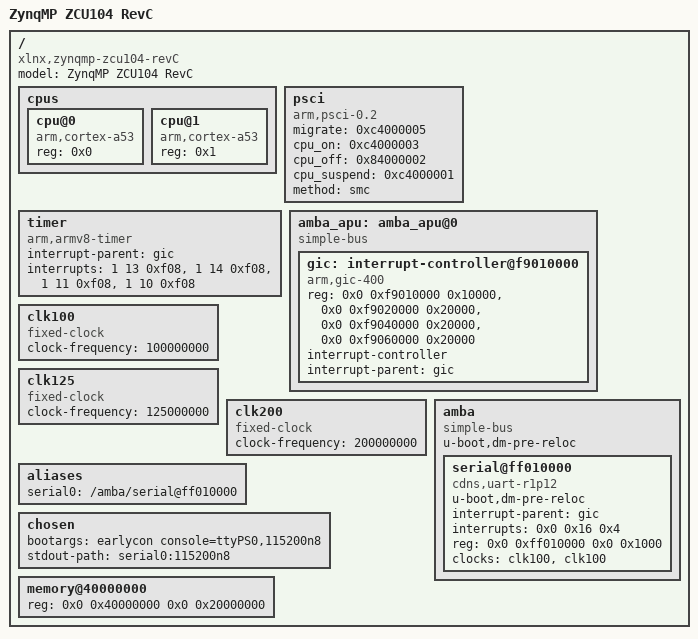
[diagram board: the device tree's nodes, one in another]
/dts-v1/;

/ {
	compatible = "xlnx,zynqmp-zcu104-revC", "xlnx,zynqmp-zcu104", "xlnx,zynqmp";
	#address-cells = <0x2>;
	#size-cells = <0x2>;
	model = "ZynqMP ZCU104 RevC";

	cpus {
		#address-cells = <0x1>;
		#size-cells = <0x0>;

		cpu@0 {
			compatible = "arm,cortex-a53", "arm,armv8";
			device_type = "cpu";
			reg = <0x0>;
		};

		cpu@1 {
			compatible = "arm,cortex-a53", "arm,armv8";
			device_type = "cpu";
			reg = <0x1>;
		};

		// cpu@2 {
		// 	compatible = "arm,cortex-a53", "arm,armv8";
		// 	device_type = "cpu";
		// 	enable-method = "psci";
		// 	reg = <0x2>;
		// };
	};

    psci {
		migrate = <0xc4000005>;
		cpu_on = <0xc4000003>;
		cpu_off = <0x84000002>;
		cpu_suspend = <0xc4000001>;
		method = "smc";
		compatible = "arm,psci-0.2", "arm,psci";
	};

	timer {
		compatible = "arm,armv8-timer";
		interrupt-parent = <&gic>;
		interrupts = <1 13 0xf08>,
			     <1 14 0xf08>,
			     <1 11 0xf08>,
			     <1 10 0xf08>;
	};

	amba_apu: amba_apu@0 {
		compatible = "simple-bus";
		#address-cells = <2>;
		#size-cells = <1>;
		ranges = <0x0 0x0 0x0 0x0 0xffffffff>;

		gic: interrupt-controller@f9010000 {
			compatible = "arm,gic-400", "arm,cortex-a15-gic";
			#interrupt-cells = <0x3>;
			reg = <0x0 0xf9010000 0x10000>,
			      <0x0 0xf9020000 0x20000>,
			      <0x0 0xf9040000 0x20000>,
			      <0x0 0xf9060000 0x20000>;
			interrupt-controller;
			interrupt-parent = <&gic>;
		};
	};

	clk100: clk100  {
		compatible = "fixed-clock";
		#clock-cells = <0x0>;
		clock-frequency = <100000000>;
	};

	clk125: clk125  {
		compatible = "fixed-clock";
		#clock-cells = <0x0>;
		clock-frequency = <125000000>;
	};

    clk200: clk200 {
		compatible = "fixed-clock";
		#clock-cells = <0x0>;
		clock-frequency = <200000000>;
	};


	amba {
		compatible = "simple-bus";
		u-boot,dm-pre-reloc;
		#address-cells = <0x2>;
		#size-cells = <0x2>;
		ranges;

		serial@ff010000 {
			u-boot,dm-pre-reloc;
			compatible = "cdns,uart-r1p12", "xlnx,xuartps";
			status = "okay";
			interrupt-parent = <&gic>;
			interrupts = <0x0 0x16 0x4>;
			reg = <0x0 0xff010000 0x0 0x1000>;
			clock-names = "uart_clk", "pclk";
			clocks = <&clk100 &clk100>;
		};

		// ethernet@ff0e0000 {
		// 	compatible = "cdns,zynqmp-gem", "cdns,gem";
		// 	status = "okay";
		// 	interrupt-parent = <&gic>;
		// 	interrupts = <0x0 0x3f 0x4 0x0 0x3f 0x4>;
		// 	reg = <0x0 0xff0e0000 0x0 0x1000>;
		// 	clock-names = "pclk", "hclk", "tx_clk";
		// 	phy-mode = "rgmii-id";
		// 	#address-cells = <1>;
		// 	#size-cells = <0>;
	    //     clocks = <&clk125>, <&clk125>, <&clk125>;
		// 	phy-handle = <&phy0>;

        //     phy0: phy@c {
        //         reg = <0xc>;
        //         ti,rx-internal-delay = <0x8>;
        //         ti,tx-internal-delay = <0xa>;
        //         ti,fifo-depth = <0x1>;
        //         ti,dp83867-rxctrl-strap-quirk;
        //     };
		// };

		// mmc@ff170000 {
        //     compatible = "xlnx,zynqmp-8.9a", "arasan,sdhci-8.9a";
        //     status = "okay";
        //     interrupt-parent = <&gic>;
        //     interrupts = <0x0 0x31 0x4>;
        //     reg = <0x0 0xff170000 0x0 0x1000>;
        //     #clock-cells = <1>;
        //     clock-names = "clk_xin", "clk_ahb";
        //     clock-output-names = "clk_out_sd0", "clk_in_sd0";
        //     clocks = <&clk200 &clk200>;
        //     xlnx,device_id = <0x1>;
        //     xlnx,mio_bank = <0x1>;
        //     no-1-8-v;
        //     disable-wp;
        //     broken-mmc-highspeed= <0x1>;
		// };

	};

	aliases {
		// ethernet0 = "/amba/ethernet@ff0e0000";
        // mmc0 = "/amba/mmc@ff170000";
		serial0 = "/amba/serial@ff010000";
	};

	chosen {
		bootargs = "earlycon console=ttyPS0,115200n8";
		stdout-path = "serial0:115200n8";
	};

    memory@40000000 {
		reg = <0x0 0x40000000 0x0 0x20000000>;
		device_type = "memory";
	};
};
